# ESP32S31_RADIO register map
Vendor: Espressif; Series: ESP32-S31; File version: 3.52
Registers are 32-bit, read-write, no defined reset value unless marked. A register's access mark holds for its fields unless they carry their own. Offsets are from the block's base; [hi:lo] are bit positions; {n}, {i} and the like mark numbered series; 'fields as' and 'values as' point back to an identical list.

## BLE_HW_CTE_RING_CONTROL — Direction-finding ring state recovered from complete ESP32-S31 ble_hw_cte.c leaves. Ordinary advertising, scanning and connection link states retain a controller-global disabled-CTE descriptor even when IQ sampling is not requested, so the baseline pointer and ownership fields are part of the minimum standalone BLE controller.
Base 0x2010199C
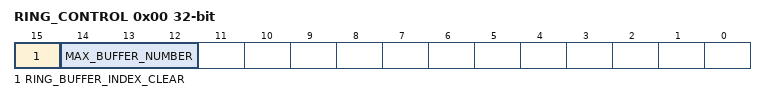
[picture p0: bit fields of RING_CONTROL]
0x00 RING_CONTROL — Project-assigned name. Reset writes the complete word as zero; independent accessors update the ring index and maximum-buffer fields through halfword RMW operations.
  [15] RING_BUFFER_INDEX_CLEAR — Project-assigned name. The named clear accessor sets bit 15. The active level and any hardware self-clear behavior remain unproven.
  [14:12] MAX_BUFFER_NUMBER — Project-assigned name. The setter truncates its argument to three bits and replaces bits 12..14; the getter returns the same field.
{0x4+8i} BUFFER_POINTER{i} (i=0..5) — Project-assigned name. Compressed controller-SRAM address of one CTE sample-ring descriptor. The setter replaces bits 0..19 and preserves the upper twelve bits.
  [19:0] COMPRESSED_DESCRIPTOR_POINTER — Project-assigned name. Low-twenty-bit controller-SRAM pointer reconstructed with the fixed 0x2f prefix and four-byte alignment.
{0x8+8i} BUFFER_STATE{i} (i=0..5) — Project-assigned name. Hardware state paired with one CTE sample-ring descriptor. Only the software-ownership flag is currently assigned.
  [31] SOFTWARE_OWNED — Project-assigned name. The named owner-clear/set leaves respectively clear and set bit 31; the paired query returns that bit.

## BLE_ISO_SCHEDULER_NOTIFY — Narrow late-feature owner for the command written by two complete ISO-path functions. A positional capability is intentional: the observed write strobe is exact, while the undocumented hardware action is not inferred from the software queue context.
Base 0x20101424
0x00 COMMAND wo — Project-assigned name. Both observed ISO-path publications write the complete value one.
  [0] TRIGGER — Project-assigned name. Observed command image is one; hardware self-clear and command meaning remain unknown.

## PHY_AGC_RECOVERED_GAPS — Sparse AGC words absent from the public platform PAC.
Base 0x20107000
0x10 WORD_0010_OPAQUE — Opaque: meaning not established. Read-modify-written by complete phy_rx_sense_set and saved/restored by complete phy_dig_reg_backup.
  [31:23] RX_SENSE — Project-assigned name. Receive-sensitivity setting complete phy_rx_sense_set publishes.
0x14 WORD_0014_OPAQUE — Opaque: meaning not established. Read-modify-written by complete phy_rx_sense_set and saved/restored by complete phy_dig_reg_backup.
  fields as WORD_0010_OPAQUE
0x1C WORD_001C_OPAQUE — Opaque: meaning not established. Read and written by complete CCA accessors and saved/restored by complete phy_dig_reg_backup.
  [7:0] CCA_THRESHOLD — Project-assigned name. Signed clear-channel-assessment threshold that complete phy_set_cca publishes (0xbf, -65, by default) and complete phy_get_cca returns.
0x50 WORD_0050_OPAQUE access not given — Opaque: meaning not established. Complete phy_get_noise_floor reads this word; hardware access semantics remain unknown.
  [9:0] NOISE_FLOOR — Project-assigned name. Ten-bit noise floor that complete phy_get_noise_floor returns sign-extended as a negative value.
0x6C WORD_006C_OPAQUE access not given — Opaque: meaning not established. Complete phy_get_rssi reads this word; hardware access semantics remain unknown.
  [15:8] RSSI_ABOVE_NOISE_FLOOR — Project-assigned name. Received signal strength above the noise floor: complete phy_get_rssi adds it to the noise floor shifted right by two.
0x74 WORD_0074_OPAQUE — Opaque: meaning not established. Complete phy_chan_filt_set read-modify-writes this word and complete phy_dig_reg_backup saves/restores it.
0xCC WORD_00CC_OPAQUE — Opaque: meaning not established. Complete phy_dig_reg_backup saves and restores this word; all field semantics remain unknown.
0xF4 WORD_00F4_OPAQUE — Opaque: meaning not established. Complete phy_wifi_rifs_mode_en read-modify-writes bit zero; all other fields remain unknown.
  [0] RIFS_MODE_ENABLE — Project-assigned name. Reduced-interframe-space receive mode enable that complete phy_wifi_rifs_mode_en publishes.
0x108 WORD_0108_OPAQUE — Opaque: meaning not established. Complete phy_rx_sense_set sets bit nine when the requested sensitivity is zero and clears it otherwise; complete phy_dig_reg_backup saves and restores the word. Field semantics remain unknown.
0x430 WORD_0430_OPAQUE — Opaque: meaning not established. Complete phy_bb_cfo_cfg replaces this word and independently read-modify-writes bit 27; the hardware field meaning remains unknown.
  [27] BIT_27_OPAQUE — Opaque: meaning not established.
0x434 WORD_0434_OPAQUE — Opaque: meaning not established. Complete phy_bb_cfo_cfg reads and replaces this word; individual hardware fields remain unnamed.
0x438 WORD_0438_OPAQUE — Opaque: meaning not established. Complete phy_bb_cfo_cfg reads and replaces this word; individual hardware fields remain unnamed.
